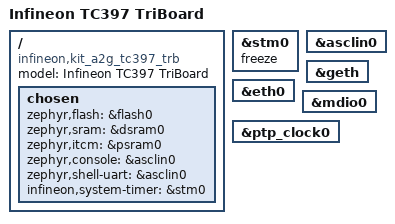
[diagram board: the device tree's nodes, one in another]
/*
 * Copyright (c) 2024 Infineon Technologies AG
 *
 * SPDX-License-Identifier: Apache-2.0
 */

/dts-v1/;

#include <infineon/tc3x/tc397xa.dtsi>
#include "kit_a2g_tc3x7_trb.dtsi"

/ {
	model = "Infineon TC397 TriBoard";
	compatible = "infineon,kit_a2g_tc397_trb",
	             "infineon,tc397",
	             "infineon,tc3x";

	chosen {
		zephyr,flash = &flash0;
		zephyr,sram = &dsram0;
		zephyr,itcm = &psram0;
		zephyr,console = &asclin0;
		zephyr,shell-uart = &asclin0;
		infineon,system-timer = &stm0;
	};
};

&stm0 {
	status = "okay";
	freeze;
};

&asclin0 {
	status = "okay";
};

&geth {
	status = "okay";
};

&eth0 {
	status = "okay";
};

&mdio0 {
	status = "okay";
};

&ptp_clock0 {
	status = "okay";
};
